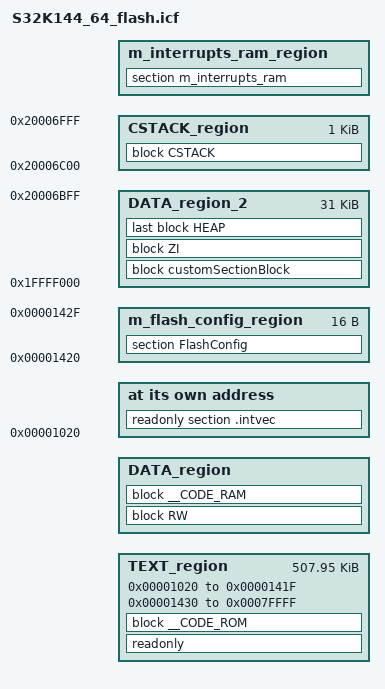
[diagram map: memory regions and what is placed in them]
/*
** ###################################################################
**     Processor:           S32K144 with 64 KB SRAM
**     Compiler:            IAR ANSI C/C++ Compiler for ARM
**
**     Abstract:
**         Linker file for the IAR ANSI C/C++ Compiler for ARM
**
**     Copyright (c) 2015-2016 Freescale Semiconductor, Inc.
**     Copyright 2017 NXP
**     All rights reserved.
**
**     THIS SOFTWARE IS PROVIDED BY NXP "AS IS" AND ANY EXPRESSED OR
**     IMPLIED WARRANTIES, INCLUDING, BUT NOT LIMITED TO, THE IMPLIED WARRANTIES
**     OF MERCHANTABILITY AND FITNESS FOR A PARTICULAR PURPOSE ARE DISCLAIMED.
**     IN NO EVENT SHALL NXP OR ITS CONTRIBUTORS BE LIABLE FOR ANY DIRECT,
**     INDIRECT, INCIDENTAL, SPECIAL, EXEMPLARY, OR CONSEQUENTIAL DAMAGES
**     (INCLUDING, BUT NOT LIMITED TO, PROCUREMENT OF SUBSTITUTE GOODS OR
**     SERVICES; LOSS OF USE, DATA, OR PROFITS; OR BUSINESS INTERRUPTION)
**     HOWEVER CAUSED AND ON ANY THEORY OF LIABILITY, WHETHER IN CONTRACT,
**     STRICT LIABILITY, OR TORT (INCLUDING NEGLIGENCE OR OTHERWISE) ARISING
**     IN ANY WAY OUT OF THE USE OF THIS SOFTWARE, EVEN IF ADVISED OF
**     THE POSSIBILITY OF SUCH DAMAGE.
**
**     http:                 www.freescale.com
**     mail:                 support@freescale.com
**
** ###################################################################
*/

/* If symbol __flash_vector_table__=1 is defined at link time
 * the interrupt vector will not be copied to RAM.
 * Warning: Using the interrupt vector from FLASH will not allow
 * INT_SYS_InstallHandler because the section is Read Only.
 */
define symbol __ram_vector_table_size__ =  isdefinedsymbol(__flash_vector_table__) ? 0 : 0x00000400;
define symbol __ram_vector_table_offset__ =  isdefinedsymbol(__flash_vector_table__) ? 0 : 0x000003FF;

define exported symbol __BOOT_ACTIVE__ = 0x01;

if (isdefinedsymbol(__BOOT_ACTIVE__)) {
// BOOTLOADER ACTIVE

/* P-Flash USATA COME P-Flash e D-Flash ) */
define symbol m_interrupts_start       = 0x00001020;  // Flash vector table - 1K
define symbol m_interrupts_end         = 0x0000141F;  // Flash vector table - 1K

define symbol m_flash_config_start     = 0x00001420;  // Flash config table - 16 byte
define symbol m_flash_config_end       = 0x0000142F;  // Flash config table - 16 byte

define symbol m_text_start             = 0x00001430; // Program Flash + Data Flash (512K -1K-16 byte)
define symbol m_text_end               = 0x0007FFFF; // Program Flash + Data Flash (512K -1K-16 byte)
/*FlexNVM - USATA COME BK EEPROM 0 D-FLASH */
/*FlexNVM - USATA COME  D-FLASH PER BOOLTLOADER  */
define symbol m_flexnvmBootloadr_start          = 0x10000000; // Bootloader
define symbol m_flexnvmBootloadr_end            = 0x10006FFF; // Bootloader

/*FlexNVM - USATA COME BK EEPROM 0 ram */
//Settare DFlashBase   in MyFlash uguale a  m_flexnvm_start          
define symbol m_flexnvm_start          = 0x10008000; // FlashNVM - used as EEPROM BK or Data Flash 64K ( USATA TUTTA COME BK EEPROM )
define symbol m_flexnvm_end            = 0x1000FFFF; // FlashNVM - used as EEPROM BK or Data Flash 64K ( USATA TUTTA COME BK EEPROM 

} else {
// NO BOOTLOADER 

/* P-Flash USATA COME P-Flash e D-Flash ) */
define symbol m_interrupts_start       = 0x00000000;  // Flash vector table - 1K
define symbol m_interrupts_end         = 0x000003FF;  // Flash vector table - 1K

define symbol m_flash_config_start     = 0x00000400;  // Flash config table - 16 byte
define symbol m_flash_config_end       = 0x0000040F;  // Flash config table - 16 byte

define symbol m_text_start             = 0x00000410; // Program Flash + Data Flash (512K -1K-16 byte)
define symbol m_text_end               = 0x0007FFFF; // Program Flash + Data Flash (512K -1K-16 byte)


/*FlexNVM - USATA COME BK EEPROM 0 D-FLASH */
define symbol m_flexnvm_start          = 0x10000000; // FlashNVM - used as EEPROM BK or Data Flash 64K ( USATA TUTTA COME BK EEPROM )
define symbol m_flexnvm_end            = 0x1000FFFF; // FlashNVM - used as EEPROM BK or Data Flash 64K ( USATA TUTTA COME BK EEPROM )
}

/*FlexRAM - USATA TUTTA COME EEPROM O RAM  */
define symbol m_flexram_start          = 0x14000000; // FlashRam - used as EEPROM or RAM 4K ( USATA TUTTA COME EEPROM )
define symbol m_flexram_end            = 0x14000FFF; // FlashRam - used as EEPROM or RAM 4K ( USATA TUTTA COME EEPROM )

/* RAM VECTOR TABLE */
define symbol m_interrupts_ram_start   = 0x1FFF8000;                                          // RAM vector table - 1K
define symbol m_interrupts_ram_end     = 0x1FFF8000 + __ram_vector_table_offset__;            // RAM vector table - 1K

/* SRAM_L USATA COME RAM */
define symbol m_data_start             = m_interrupts_ram_start + __ram_vector_table_size__;  // RAM_L banco 0 di RAM - 31K
define symbol m_data_end               = 0x1FFFEFFF;

/* SRAM_U USATA COME RAM */
define symbol m_data_2_start           = 0x1FFFF000;
define symbol m_data_2_end             = 0x20006FFF;                                          // RAM_L banco 1 di RAM - 28K

/* Sizes */
if (isdefinedsymbol(__stack_size__)) {
  define symbol __size_cstack__        = __stack_size__;
} else {
  define symbol __size_cstack__        = 0x00000400;
}

if (isdefinedsymbol(__heap_size__)) {
  define symbol __size_heap__          = __heap_size__;
} else {
  define symbol __size_heap__          = 0x00000400;
}

define exported symbol __VECTOR_TABLE          = m_interrupts_start;
define exported symbol __VECTOR_RAM            = isdefinedsymbol(__flash_vector_table__) ? m_interrupts_start : m_interrupts_ram_start;
define exported symbol __RAM_VECTOR_TABLE_SIZE = __ram_vector_table_size__;

define memory mem with size = 4G;
define region m_flash_config_region   = mem:[from m_flash_config_start to m_flash_config_end];
define region TEXT_region             = mem:[from m_interrupts_start to m_interrupts_end]
                                      | mem:[from m_text_start to m_text_end];
define region DATA_region             = mem:[from m_data_start to m_data_end];
define region DATA_region_2           = mem:[from m_data_2_start to m_data_2_end-__size_cstack__];
define region CSTACK_region           = mem:[from m_data_2_end-__size_cstack__+1 to m_data_2_end];
define region m_interrupts_ram_region = mem:[from m_interrupts_ram_start to m_interrupts_ram_end];


define block CSTACK    with alignment = 8, size = __size_cstack__   { };
define block HEAP      with alignment = 8, size = __size_heap__     { };
define block RW        { readwrite };
define block ZI        { zi };

/* Custom Section Block that can be used to place data at absolute address. */
/* Use __attribute__((section (".customSection"))) to place data here. */
define block customSectionBlock { section .customSection };

define block __CODE_ROM   { section .textrw_init };
define block __CODE_RAM   { section .textrw  };

initialize manually       { section .textrw };
initialize manually       { section .bss };
initialize manually       { section .customSection };
initialize manually       { section .data };
initialize manually       { section __DLIB_PERTHREAD };
//<SCST_INIT>
do not initialize         { section .noinit, section .bss, section .data, section __DLIB_PERTHREAD, section .customSection };

place at address mem: m_interrupts_start    { readonly section .intvec };
place in m_flash_config_region              { section FlashConfig };
place in TEXT_region                        { readonly };
place in TEXT_region                        { block __CODE_ROM };
place in DATA_region                        { block RW };
//<SCST_ADDR>
place in DATA_region                        { block __CODE_RAM };
place in DATA_region_2                      { block customSectionBlock };
place in DATA_region_2                      { block ZI };
place in DATA_region_2                      { last block HEAP };
place in CSTACK_region                      { block CSTACK };
place in m_interrupts_ram_region            { section m_interrupts_ram };

define symbol __ICFEDIT_region_RAM_start__ = 0x1FFF8000;
define symbol __ICFEDIT_region_RAM_end__   = 0x20006FFF;
define symbol __STACK_BOTTOM_CTRL__ = m_data_2_end-__size_cstack__+1-16;
export symbol __STACK_BOTTOM_CTRL__;
export symbol __ICFEDIT_region_RAM_start__;
export symbol __ICFEDIT_region_RAM_end__;

//define block STACK_BOTTOM_B  with alignment = 8, size = __ICFEDIT_size_stack_bottom__  { section STACK_BOTTOM };

